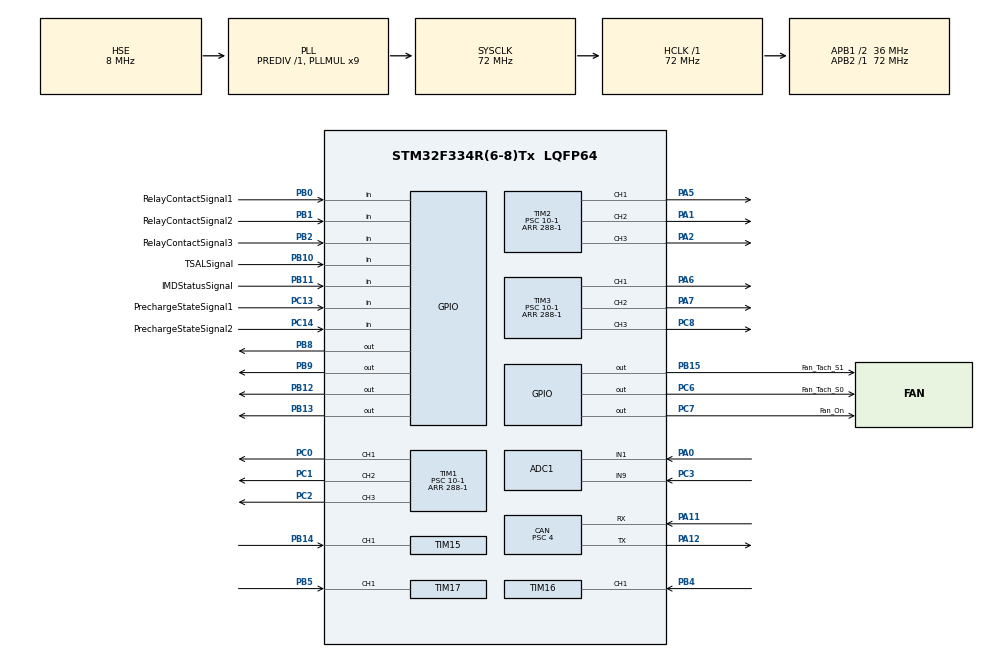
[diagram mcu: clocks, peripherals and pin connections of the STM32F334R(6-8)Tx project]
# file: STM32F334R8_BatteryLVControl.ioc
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ADC1.Channel-0\#ChannelRegularConversion=ADC_CHANNEL_1
ADC1.Channel-1\#ChannelRegularConversion=ADC_CHANNEL_9
ADC1.ContinuousConvMode=ENABLE
ADC1.DMAContinuousRequests=ENABLE
ADC1.NbrOfConversion=2
ADC1.NbrOfConversionFlag=1
ADC1.Offset-0\#ChannelRegularConversion=0
ADC1.Offset-1\#ChannelRegularConversion=0
ADC1.OffsetNumber-0\#ChannelRegularConversion=ADC_OFFSET_NONE
ADC1.OffsetNumber-1\#ChannelRegularConversion=ADC_OFFSET_NONE
ADC1.Rank-0\#ChannelRegularConversion=1
ADC1.Rank-1\#ChannelRegularConversion=2
ADC1.SamplingTime-0\#ChannelRegularConversion=ADC_SAMPLETIME_1CYCLE_5
ADC1.SamplingTime-1\#ChannelRegularConversion=ADC_SAMPLETIME_1CYCLE_5
ADC1.SamplingTimeOPAMP-1\#ChannelRegularConversion=ADC_SAMPLETIME_61CYCLES_5
ADC1.SubFamily=STM32F334x8
ADC1.master=1
CAN.BS1=CAN_BS1_7TQ
CAN.CalculateBaudRate=1000000
CAN.CalculateTimeBit=1000
CAN.CalculateTimeQuantum=111.11111111111111
CAN.Prescaler=4
Dma.ADC1.0.Direction=DMA_PERIPH_TO_MEMORY
Dma.ADC1.0.Instance=DMA1_Channel1
Dma.ADC1.0.MemDataAlignment=DMA_MDATAALIGN_WORD
Dma.ADC1.0.MemInc=DMA_MINC_ENABLE
Dma.ADC1.0.Mode=DMA_CIRCULAR
Dma.ADC1.0.PeriphDataAlignment=DMA_PDATAALIGN_WORD
Dma.ADC1.0.PeriphInc=DMA_PINC_DISABLE
Dma.ADC1.0.Priority=DMA_PRIORITY_LOW
Dma.Request0=ADC1
Mcu.Family=STM32F3
Mcu.Name=STM32F334R(6-8)Tx
Mcu.Package=LQFP64
NVIC.CAN_RX0_IRQn=true\:0\:0\:false\:true\:true\:1\:true\:true\:true
NVIC.CAN_RX1_IRQn=true\:0\:0\:false\:true\:true\:2\:true\:true\:true
NVIC.DMA1_Channel1_IRQn=true\:0\:0\:false\:false\:true\:false\:true\:true
NVIC.PriorityGroup=NVIC_PRIORITYGROUP_4
NVIC.TIM1_BRK_TIM15_IRQn=true\:0\:0\:false\:false\:true\:true\:true\:true
NVIC.TIM1_TRG_COM_TIM17_IRQn=true\:0\:0\:false\:false\:true\:true\:true\:true
NVIC.TIM1_UP_TIM16_IRQn=true\:0\:0\:false\:false\:true\:true\:true\:true
PA0.Mode=IN1-Single-Ended
PA0.Signal=ADC1_IN1
PA1.Signal=S_TIM2_CH2
PA11.GPIO_Mode=GPIO_MODE_AF_PP
PA11.GPIO_PuPd=GPIO_NOPULL
PA11.GPIO_Speed=GPIO_SPEED_FREQ_HIGH
PA11.Mode=CAN_Activate
PA11.Signal=CAN_RX
PA12.Mode=CAN_Activate
PA12.Signal=CAN_TX
PA13.Mode=Trace_Asynchronous_SW
PA13.Signal=SYS_JTMS-SWDIO
PA14.Mode=Trace_Asynchronous_SW
PA14.Signal=SYS_JTCK-SWCLK
PA2.Signal=S_TIM2_CH3
PA3.Signal=ADC1_IN4
PA4.Signal=ADC2_IN1
PA5.Signal=S_TIM2_CH1_ETR
PA6.Signal=S_TIM3_CH1
PA7.Signal=S_TIM3_CH2
PB0.GPIO_Label=RelayContactSignal1
PB0.Signal=GPIO_Input
PB1.GPIO_Label=RelayContactSignal2
PB1.Signal=GPIO_Input
PB10.GPIO_Label=TSALSignal
PB10.Signal=GPIO_Input
PB11.GPIO_Label=IMDStatusSignal
PB11.Signal=GPIO_Input
PB12.Signal=GPIO_Output
PB13.Signal=GPIO_Output
PB14.Signal=S_TIM15_CH1
PB15.GPIO_Label=Fan_Tach_S1
PB15.Signal=GPIO_Output
PB2.GPIO_Label=RelayContactSignal3
PB2.Signal=GPIO_Input
PB3.Mode=Trace_Asynchronous_SW
PB3.Signal=SYS_JTDO-TRACESWO
PB4.Signal=S_TIM16_CH1
PB5.Signal=S_TIM17_CH1
PB8.Signal=GPIO_Output
PB9.Signal=GPIO_Output
PC0.Signal=S_TIM1_CH1
PC1.Signal=S_TIM1_CH2
PC13.GPIO_Label=PrechargeStateSignal1
PC13.Signal=GPIO_Input
PC14\ /\ OSC32_IN.GPIO_Label=PrechargeStateSignal2
PC14\ /\ OSC32_IN.Signal=GPIO_Input
PC2.Signal=S_TIM1_CH3
PC3.Signal=ADCx_IN9
PC4.Signal=ADC2_IN5
PC5.Signal=ADC2_IN11
PC6.GPIO_Label=Fan_Tach_S0
PC6.Signal=GPIO_Output
PC7.GPIO_Label=Fan_On
PC7.Signal=GPIO_Output
PC8.Signal=S_TIM3_CH3
PF0\ /\ OSC_IN.Mode=HSE-External-Oscillator
PF0\ /\ OSC_IN.Signal=RCC_OSC_IN
PF1\ /\ OSC_OUT.Mode=HSE-External-Oscillator
PF1\ /\ OSC_OUT.Signal=RCC_OSC_OUT
ProjectManager.HeapSize=0x200
ProjectManager.StackSize=0x400
ProjectManager.TargetToolchain=STM32CubeIDE
RCC.AHBFreq_Value=72000000
RCC.APB1CLKDivider=RCC_HCLK_DIV2
RCC.APB1Freq_Value=36000000
RCC.APB1TimFreq_Value=72000000
RCC.APB2Freq_Value=72000000
RCC.APB2TimFreq_Value=72000000
RCC.CortexFreq_Value=72000000
RCC.HCLKFreq_Value=72000000
RCC.HSE_VALUE=8000000
RCC.HSI_VALUE=8000000
RCC.LSE_VALUE=32768
RCC.PLLMUL=RCC_PLL_MUL9
RCC.PLLSourceVirtual=RCC_PLLSOURCE_HSE
RCC.SYSCLKFreq_VALUE=72000000
RCC.SYSCLKSourceVirtual=RCC_SYSCLKSOURCE_PLLCLK
SH.ADCx_IN9.0=ADC1_IN9,IN9-Single-Ended
SH.S_TIM15_CH1.0=TIM15_CH1,Input_Capture1_from_TI1
SH.S_TIM16_CH1.0=TIM16_CH1,Input_Capture1_from_TI1
SH.S_TIM17_CH1.0=TIM17_CH1,Input_Capture1_from_TI1
SH.S_TIM1_CH1.0=TIM1_CH1,PWM Generation1 CH1
SH.S_TIM1_CH2.0=TIM1_CH2,PWM Generation2 CH2
SH.S_TIM1_CH3.0=TIM1_CH3,PWM Generation3 CH3
SH.S_TIM2_CH1_ETR.0=TIM2_CH1,PWM Generation1 CH1
SH.S_TIM2_CH2.0=TIM2_CH2,PWM Generation2 CH2
SH.S_TIM2_CH3.0=TIM2_CH3,PWM Generation3 CH3
SH.S_TIM3_CH1.0=TIM3_CH1,PWM Generation1 CH1
SH.S_TIM3_CH2.0=TIM3_CH2,PWM Generation2 CH2
SH.S_TIM3_CH3.0=TIM3_CH3,PWM Generation3 CH3
TIM1.AutoReloadPreload=TIM_AUTORELOAD_PRELOAD_ENABLE
TIM1.Channel-PWM\ Generation1\ CH1=TIM_CHANNEL_1
TIM1.Channel-PWM\ Generation2\ CH2=TIM_CHANNEL_2
TIM1.Channel-PWM\ Generation3\ CH3=TIM_CHANNEL_3
TIM1.OCFastMode_PWM-PWM\ Generation1\ CH1=TIM_OCFAST_ENABLE
TIM1.OCFastMode_PWM-PWM\ Generation2\ CH2=TIM_OCFAST_ENABLE
TIM1.OCFastMode_PWM-PWM\ Generation3\ CH3=TIM_OCFAST_ENABLE
TIM1.Period=288-1
TIM1.Prescaler=10-1
TIM1.Pulse-PWM\ Generation1\ CH1=0
TIM1.Pulse-PWM\ Generation2\ CH2=0
TIM1.Pulse-PWM\ Generation3\ CH3=0
TIM1.TIM_MasterOutputTrigger=TIM_TRGO_UPDATE
TIM1.TIM_MasterOutputTrigger2=TIM_TRGO2_UPDATE
TIM15.AutoReloadPreload=TIM_AUTORELOAD_PRELOAD_ENABLE
TIM15.Channel-Input_Capture1_from_TI1=TIM_CHANNEL_1
TIM15.ICFilter_CH1=15
TIM15.ICPolarity_CH1=TIM_INPUTCHANNELPOLARITY_RISING
TIM15.Period=80-1
TIM15.Prescaler=72-1
TIM16.AutoReloadPreload=TIM_AUTORELOAD_PRELOAD_ENABLE
TIM16.Channel=TIM_CHANNEL_1
TIM16.ICFilter_CH1=15
TIM16.ICPolarity_CH1=TIM_INPUTCHANNELPOLARITY_RISING
TIM16.Period=80-1
TIM16.Prescaler=72-1
TIM17.AutoReloadPreload=TIM_AUTORELOAD_PRELOAD_ENABLE
TIM17.Channel=TIM_CHANNEL_1
TIM17.ICFilter_CH1=15
TIM17.ICPolarity_CH1=TIM_INPUTCHANNELPOLARITY_RISING
TIM17.Period=80-1
TIM17.Prescaler=72-1
TIM2.AutoReloadPreload=TIM_AUTORELOAD_PRELOAD_ENABLE
TIM2.Channel-PWM\ Generation1\ CH1=TIM_CHANNEL_1
TIM2.Channel-PWM\ Generation2\ CH2=TIM_CHANNEL_2
TIM2.Channel-PWM\ Generation3\ CH3=TIM_CHANNEL_3
TIM2.OCFastMode_PWM-PWM\ Generation1\ CH1=TIM_OCFAST_ENABLE
TIM2.OCFastMode_PWM-PWM\ Generation2\ CH2=TIM_OCFAST_ENABLE
TIM2.OCFastMode_PWM-PWM\ Generation3\ CH3=TIM_OCFAST_ENABLE
TIM2.Period=288-1
TIM2.Prescaler=10-1
TIM2.Pulse-PWM\ Generation2\ CH2=0
TIM2.Pulse-PWM\ Generation3\ CH3=0
TIM2.TIM_MasterOutputTrigger=TIM_TRGO_UPDATE
TIM3.AutoReloadPreload=TIM_AUTORELOAD_PRELOAD_ENABLE
TIM3.Channel-PWM\ Generation1\ CH1=TIM_CHANNEL_1
TIM3.Channel-PWM\ Generation2\ CH2=TIM_CHANNEL_2
TIM3.Channel-PWM\ Generation3\ CH3=TIM_CHANNEL_3
TIM3.OCFastMode_PWM-PWM\ Generation1\ CH1=TIM_OCFAST_ENABLE
TIM3.OCFastMode_PWM-PWM\ Generation2\ CH2=TIM_OCFAST_ENABLE
TIM3.OCFastMode_PWM-PWM\ Generation3\ CH3=TIM_OCFAST_ENABLE
TIM3.Period=288-1
TIM3.Prescaler=10-1
TIM3.Pulse-PWM\ Generation1\ CH1=0
TIM3.Pulse-PWM\ Generation2\ CH2=0
TIM3.Pulse-PWM\ Generation3\ CH3=0
TIM3.TIM_MasterOutputTrigger=TIM_TRGO_UPDATE
VP_TIM15_VS_ClockSourceINT.Mode=Internal
VP_TIM16_VS_ClockSourceINT.Mode=Enable_Timer
VP_TIM17_VS_ClockSourceINT.Mode=Enable_Timer
VP_TIM1_VS_ClockSourceINT.Mode=Internal
VP_TIM2_VS_ClockSourceINT.Mode=Internal
VP_TIM3_VS_ClockSourceINT.Mode=Internal
board=custom

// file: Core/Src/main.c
/* USER CODE BEGIN Header */
/**
  ******************************************************************************
  * @file           : main.c
  * @brief          : Main program body
  ******************************************************************************
  * @attention
  *
  * <h2><center>&copy; Copyright (c) 2021 STMicroelectronics.
  * All rights reserved.</center></h2>
  *
  * This software component is licensed by ST under BSD 3-Clause license,
  * the "License"; You may not use this file except in compliance with the
  * License. You may obtain a copy of the License at:
  *                        opensource.org/licenses/BSD-3-Clause
  *
  ******************************************************************************
  */
/* USER CODE END Header */
#include "main.h"
#include "adc.h"
#include "can.h"
#include "dma.h"
#include "tim.h"
#include "gpio.h"

/* USER CODE BEGIN Includes */
#include "GAS_Scheduler.h"
/* USER CODE END Includes */

void SystemClock_Config(void);
static void MX_NVIC_Init(void);

int main(void)
{

  /* MCU Configuration--------------------------------------------------------*/

  /* Reset of all peripherals, Initializes the Flash interface and the Systick. */
  HAL_Init();

  /* Configure the system clock */
  SystemClock_Config();

  /* Initialize all configured peripherals */
  MX_GPIO_Init();
  MX_CAN_Init();
  MX_TIM1_Init();
  MX_TIM2_Init();
  MX_TIM3_Init();
  MX_TIM15_Init();
  MX_ADC1_Init();
  MX_TIM16_Init();
  MX_DMA_Init();
  MX_TIM17_Init();

  /* Initialize interrupts */
  MX_NVIC_Init();
  /* USER CODE BEGIN 2 */
  GAS_Scheduler_init();

  /* USER CODE END 2 */

  /* Infinite loop */
  while (1)
  {

    /* USER CODE BEGIN 3 */
	  GAS_Scheduler();
  }
  /* USER CODE END 3 */
}

void SystemClock_Config(void)
{
  RCC_OscInitTypeDef RCC_OscInitStruct = {0};
  RCC_ClkInitTypeDef RCC_ClkInitStruct = {0};
  RCC_PeriphCLKInitTypeDef PeriphClkInit = {0};

  /** Initializes the RCC Oscillators according to the specified parameters
  * in the RCC_OscInitTypeDef structure.
  */
  RCC_OscInitStruct.OscillatorType = RCC_OSCILLATORTYPE_HSE;
  RCC_OscInitStruct.HSEState = RCC_HSE_ON;
  RCC_OscInitStruct.HSEPredivValue = RCC_HSE_PREDIV_DIV1;
  RCC_OscInitStruct.HSIState = RCC_HSI_ON;
  RCC_OscInitStruct.PLL.PLLState = RCC_PLL_ON;
  RCC_OscInitStruct.PLL.PLLSource = RCC_PLLSOURCE_HSE;
  RCC_OscInitStruct.PLL.PLLMUL = RCC_PLL_MUL9;
  if (HAL_RCC_OscConfig(&RCC_OscInitStruct) != HAL_OK)
  {
    Error_Handler();
  }
  /** Initializes the CPU, AHB and APB buses clocks
  */
  RCC_ClkInitStruct.ClockType = RCC_CLOCKTYPE_HCLK|RCC_CLOCKTYPE_SYSCLK
                              |RCC_CLOCKTYPE_PCLK1|RCC_CLOCKTYPE_PCLK2;
  RCC_ClkInitStruct.SYSCLKSource = RCC_SYSCLKSOURCE_PLLCLK;
  RCC_ClkInitStruct.AHBCLKDivider = RCC_SYSCLK_DIV1;
  RCC_ClkInitStruct.APB1CLKDivider = RCC_HCLK_DIV2;
  RCC_ClkInitStruct.APB2CLKDivider = RCC_HCLK_DIV1;

  if (HAL_RCC_ClockConfig(&RCC_ClkInitStruct, FLASH_LATENCY_2) != HAL_OK)
  {
    Error_Handler();
  }
  PeriphClkInit.PeriphClockSelection = RCC_PERIPHCLK_TIM1|RCC_PERIPHCLK_ADC12;
  PeriphClkInit.Adc12ClockSelection = RCC_ADC12PLLCLK_DIV1;
  PeriphClkInit.Tim1ClockSelection = RCC_TIM1CLK_HCLK;
  if (HAL_RCCEx_PeriphCLKConfig(&PeriphClkInit) != HAL_OK)
  {
    Error_Handler();
  }
}

/**
  * @brief NVIC Configuration.
  * @retval None
  */
static void MX_NVIC_Init(void)
{
  /* CAN_RX0_IRQn interrupt configuration */
  HAL_NVIC_SetPriority(CAN_RX0_IRQn, 0, 0);
  HAL_NVIC_EnableIRQ(CAN_RX0_IRQn);
  /* CAN_RX1_IRQn interrupt configuration */
  HAL_NVIC_SetPriority(CAN_RX1_IRQn, 0, 0);
  HAL_NVIC_EnableIRQ(CAN_RX1_IRQn);
}

void Error_Handler(void)
{
  __disable_irq();
  while (1)
  {
  }
}

/************************ (C) COPYRIGHT STMicroelectronics *****END OF FILE****/
